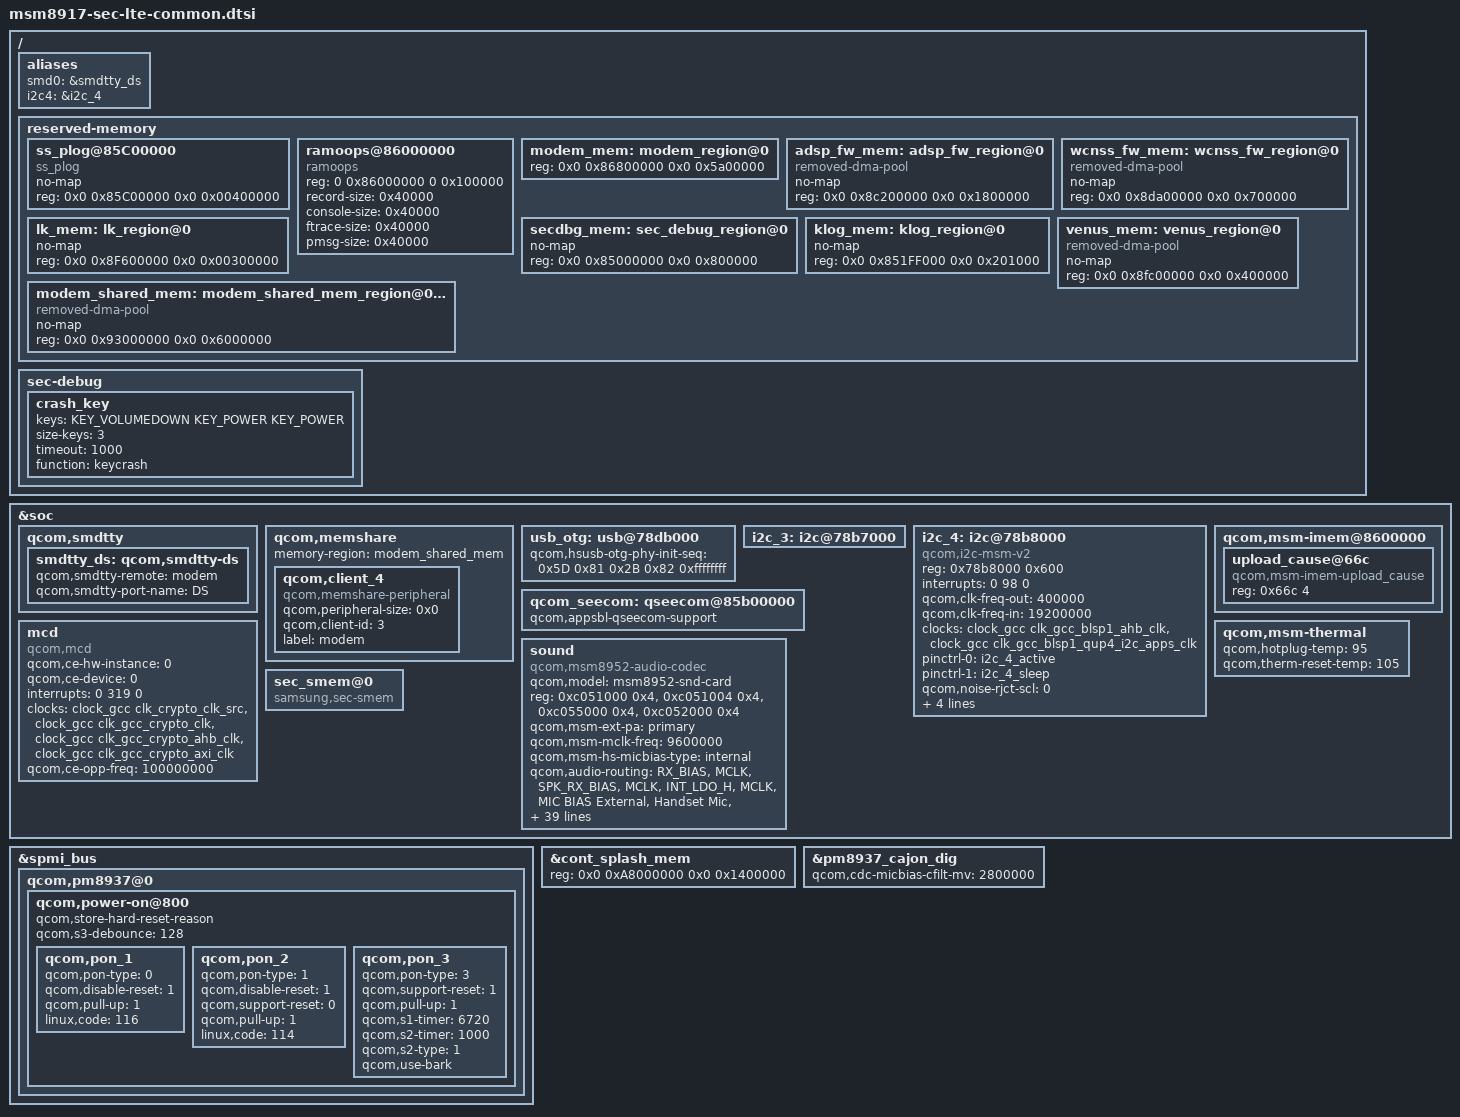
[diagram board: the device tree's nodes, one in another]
/*
 * Copyright (c) 2015, The Linux Foundation. All rights reserved.
 *
 * This program is free software; you can redistribute it and/or modify
 * it under the terms of the GNU General Public License version 2 and
 * only version 2 as published by the Free Software Foundation.
 *
 * This program is distributed in the hope that it will be useful,
 * but WITHOUT ANY WARRANTY; without even the implied warranty of
 * MERCHANTABILITY or FITNESS FOR A PARTICULAR PURPOSE.  See the
 * GNU General Public License for more details.
 */

#include <dt-bindings/input/input.h>

/ {
	aliases {
		smd0 = &smdtty_ds;

		/delete-property/ i2c4;
		i2c4 = &i2c_4;
	};
};

&soc {
	qcom,smdtty {
		smdtty_ds: qcom,smdtty-ds {
			qcom,smdtty-remote = "modem";
			qcom,smdtty-port-name = "DS";
		};

	};

	qcom,memshare {
		memory-region = <&modem_shared_mem>;

		qcom,client_4 {
			compatible = "qcom,memshare-peripheral";
			qcom,peripheral-size = <0x0>;
			qcom,client-id = <3>;	/* vendor */
			label = "modem";
		};
	};

	/delete-node/ smbcharger_charger_otg;

	usb_otg: usb@78db000 {
		/delete-property/ vbus_otg-supply;
	};

	i2c_3: i2c@78b7000 {
		/delete-property/ status;
	};

	i2c_4: i2c@78b8000 { /* BLSP1 QUP4 */
		compatible = "qcom,i2c-msm-v2";
		#address-cells = <1>;
		#size-cells = <0>;
		reg-names = "qup_phys_addr";
		reg = <0x78b8000 0x600>;
		interrupt-names = "qup_irq";
		interrupts = <0 98 0>;
		qcom,clk-freq-out = <400000>;
		qcom,clk-freq-in  = <19200000>;
		clock-names = "iface_clk", "core_clk";
		clocks = <&clock_gcc clk_gcc_blsp1_ahb_clk>,
			<&clock_gcc clk_gcc_blsp1_qup4_i2c_apps_clk>;

		pinctrl-names = "i2c_active", "i2c_sleep";
		pinctrl-0 = <&i2c_4_active>;
		pinctrl-1 = <&i2c_4_sleep>;
		qcom,noise-rjct-scl = <0>;
		qcom,noise-rjct-sda = <0>;
		qcom,master-id = <86>;
		dmas = <&dma_blsp1 10 64 0x20000020 0x20>,
			<&dma_blsp1 11 32 0x20000020 0x20>;
		dma-names = "tx", "rx";
	};

	qcom,msm-imem@8600000 {
                upload_cause@66c {
                        compatible = "qcom,msm-imem-upload_cause";
                        reg = <0x66c 4>;
                };
        };

	qcom_seecom: qseecom@85b00000 {
		qcom,appsbl-qseecom-support;
	};

	mcd: mcd {
		compatible = "qcom,mcd";
		qcom,ce-hw-instance = <0>;
		qcom,ce-device = <0>;
		interrupts = <0 319 0>;
		interrupt-names = "mcd_irq";
		clocks = <&clock_gcc clk_crypto_clk_src>,
			 <&clock_gcc clk_gcc_crypto_clk>,
			 <&clock_gcc clk_gcc_crypto_ahb_clk>,
			 <&clock_gcc clk_gcc_crypto_axi_clk>;
		clock-names = "core_clk_src", "core_clk",
				"iface_clk", "bus_clk";
		qcom,ce-opp-freq = <100000000>;
	};

	sound {
		status = "okay";
		compatible = "qcom,msm8952-audio-codec";
		qcom,model = "msm8952-snd-card";
		reg = <0xc051000 0x4>,
		      <0xc051004 0x4>,
		      <0xc055000 0x4>,
		      <0xc052000 0x4>;
		reg-names = "csr_gp_io_mux_mic_ctl",
			    "csr_gp_io_mux_spkr_ctl",
			    "csr_gp_io_lpaif_pri_pcm_pri_mode_muxsel",
			    "csr_gp_io_mux_quin_ctl";

		qcom,msm-ext-pa = "primary";
		qcom,msm-mclk-freq = <9600000>;
		qcom,msm-hs-micbias-type = "internal";
		/delete-property/qcom,hdmi-dba-codec-rx;
		/delete-property/qcom,msm-mbhc-hphl-swh;
		/delete-property/qcom,msm-mbhc-gnd-swh;
		/delete-property/qcom,msm-micbias1-ext-cap;
		/delete-property/qcom,cdc-us-euro-gpios;
		qcom,audio-routing =
			"RX_BIAS", "MCLK",
			"SPK_RX_BIAS", "MCLK",
			"INT_LDO_H", "MCLK",
			"MIC BIAS External", "Handset Mic",
			"MIC BIAS External2", "Headset Mic",
			"MIC BIAS External", "Secondary Mic",
			"AMIC1", "MIC BIAS External",
			"AMIC2", "MIC BIAS External2",
			"AMIC3", "MIC BIAS External";

		qcom,msm-gpios =
			"pri_i2s";
		qcom,pinctrl-names =
			"all_off",
			"pri_i2s_act";
		pinctrl-names =
			"all_off",
			"pri_i2s_act";
		pinctrl-0 = <&cdc_pdm_lines_sus &cdc_pdm_lines_2_sus>;
		pinctrl-1 = <&cdc_pdm_lines_act &cdc_pdm_lines_2_act>;

		asoc-platform = <&pcm0>, <&pcm1>, <&pcm2>, <&voip>, <&voice>,
				<&loopback>, <&compress>, <&hostless>,
				<&afe>, <&lsm>, <&routing>, <&lpa>;
		asoc-platform-names = "msm-pcm-dsp.0", "msm-pcm-dsp.1",
				"msm-pcm-dsp.2", "msm-voip-dsp",
				"msm-pcm-voice", "msm-pcm-loopback",
				"msm-compress-dsp", "msm-pcm-hostless",
				"msm-pcm-afe", "msm-lsm-client",
				"msm-pcm-routing", "msm-pcm-lpa";
		asoc-cpu = <&dai_pri_auxpcm>,
				<&dai_mi2s0>, <&dai_mi2s1>,
				<&dai_mi2s2>, <&dai_mi2s3>,
				<&dai_mi2s5>, <&dai_mi2s6>,
				<&bt_sco_rx>, <&bt_sco_tx>,
				<&int_fm_rx>, <&int_fm_tx>,
				<&afe_pcm_rx>, <&afe_pcm_tx>,
				<&afe_proxy_rx>, <&afe_proxy_tx>,
				<&incall_record_rx>, <&incall_record_tx>,
				<&incall_music_rx>, <&incall_music_2_rx>;
		asoc-cpu-names = "msm-dai-q6-auxpcm.1",
				"msm-dai-q6-mi2s.0", "msm-dai-q6-mi2s.1",
				"msm-dai-q6-mi2s.2", "msm-dai-q6-mi2s.3",
				"msm-dai-q6-mi2s.5", "msm-dai-q6-mi2s.6",
				"msm-dai-q6-dev.12288", "msm-dai-q6-dev.12289",
				"msm-dai-q6-dev.12292", "msm-dai-q6-dev.12293",
				"msm-dai-q6-dev.224", "msm-dai-q6-dev.225",
				"msm-dai-q6-dev.241", "msm-dai-q6-dev.240",
				"msm-dai-q6-dev.32771", "msm-dai-q6-dev.32772",
				"msm-dai-q6-dev.32773", "msm-dai-q6-dev.32770";

		asoc-codec = <&stub_codec>, <&pm8937_cajon_dig>;
		asoc-codec-names = "msm-stub-codec.1", "cajon_codec";
	};	

	qcom,msm-thermal {
		qcom,hotplug-temp = <95>;
		qcom,therm-reset-temp = <105>;
	};

	sec_smem@0 {
		compatible = "samsung,sec-smem";
		status = "okay";
	};
};

/ {
	reserved-memory {
		ss_plog@85C00000 {
			compatible = "ss_plog";
			no-map;
			reg = <0x0 0x85C00000 0x0 0x00400000>;
		};
		ramoops@86000000 {
			compatible = "ramoops";
			reg = <0 0x86000000 0 0x100000>;
			record-size = <0x40000>;
			console-size = <0x40000>;
			ftrace-size = <0x40000>;
			pmsg-size = <0x40000>;
		};
		modem_mem: modem_region@0 {
			reg = <0x0 0x86800000 0x0 0x5a00000>;
		};

		adsp_fw_mem: adsp_fw_region@0 {
			compatible = "removed-dma-pool";
			no-map;
			reg = <0x0 0x8c200000 0x0 0x1800000>;
		};

		wcnss_fw_mem: wcnss_fw_region@0 {
			compatible = "removed-dma-pool";
			no-map;
			reg = <0x0 0x8da00000 0x0 0x700000>;
		};

		lk_mem: lk_region@0 {
			no-map;
			reg = <0x0 0x8F600000 0x0 0x00300000>;
		};
		
		secdbg_mem: sec_debug_region@0 {
			no-map;
			reg = <0x0 0x85000000 0x0 0x800000>;
		};
		
		klog_mem: klog_region@0 {
			no-map;
			reg = <0x0 0x851FF000 0x0 0x201000>;
		};

		modem_shared_mem: modem_shared_mem_region@0x93000000 {
			compatible = "removed-dma-pool";
			no-map;
			reg = <0x0 0x93000000 0x0 0x6000000>;
		};

		/delete-node/ venus_region@0;
		venus_mem: venus_region@0 {
			compatible = "removed-dma-pool";
			no-map;
			reg = <0x0 0x8fc00000 0x0 0x400000>;
		};
	};

	sec-debug {
		crash_key {
			keys = <KEY_VOLUMEDOWN KEY_POWER KEY_POWER>;
			size-keys = <3>;
			timeout = <1000>;	/* default = 1000msec */
			function = "keycrash";
		};

		/* tsp_dump {
			keys = <KEY_VOLUMEUP KEY_HOMEPAGE KEY_HOMEPAGE>;
			size-keys = <3>;
			timeout = <1000>;
			function = "tsp_dump";
		}; */
	};

};

&spmi_bus {
	qcom,pm8937@0 {
		qcom,power-on@800 {
			qcom,store-hard-reset-reason;

			qcom,s3-debounce = <128>;
			qcom,pon_1 {
				qcom,pon-type = <0>;
				qcom,disable-reset = <1>;
				qcom,pull-up = <1>;
				linux,code = <116>;
			};

			qcom,pon_2 {
				qcom,pon-type = <1>;
				qcom,disable-reset = <1>;
				qcom,support-reset = <0>;
				qcom,pull-up = <1>;
				linux,code = <114>;
			};

			qcom,pon_3 {
				qcom,pon-type = <3>;
				qcom,support-reset = <1>;
				qcom,pull-up = <1>;
				qcom,s1-timer = <6720>;
				qcom,s2-timer = <1000>;
				qcom,s2-type = <1>;
				qcom,use-bark;
			};
		};
	};
};

&cont_splash_mem {
	reg = <0x0 0xA8000000 0x0 0x1400000>;
};

&usb_otg {
	qcom,hsusb-otg-phy-init-seq = 
					<0x5D 0x81 0x2B 0x82 0xffffffff>;
};

&pm8937_cajon_dig {
	qcom,cdc-micbias-cfilt-mv = <2800000>;
};
